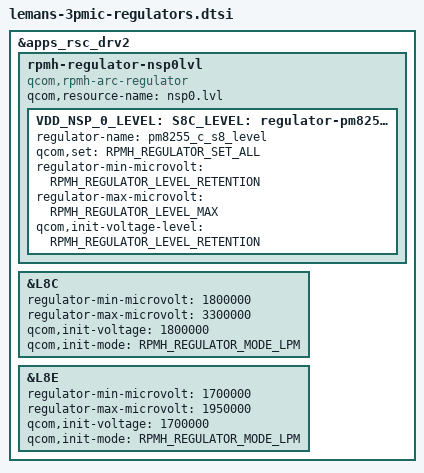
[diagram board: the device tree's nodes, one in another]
#include "lemans-4pmic-regulators.dtsi"

&apps_rsc_drv2 {
	/delete-node/ rpmh-regulator-nsp0lvl;
	/delete-node/ rpmh-regulator-nsp1lvl;

	rpmh-regulator-nsp0lvl {
		compatible = "qcom,rpmh-arc-regulator";
		qcom,resource-name = "nsp0.lvl";
		VDD_NSP_0_LEVEL:
		S8C_LEVEL:
		pm8255_c_s8_level: regulator-pm8255_c-s8-level {
			regulator-name = "pm8255_c_s8_level";
			qcom,set = <RPMH_REGULATOR_SET_ALL>;
			regulator-min-microvolt =
				<RPMH_REGULATOR_LEVEL_RETENTION>;
			regulator-max-microvolt =
				<RPMH_REGULATOR_LEVEL_MAX>;
			qcom,init-voltage-level =
				<RPMH_REGULATOR_LEVEL_RETENTION>;
		};
	};

	&L8C {
		regulator-min-microvolt = <1800000>;
		regulator-max-microvolt = <3300000>;
		qcom,init-voltage = <1800000>;
		qcom,init-mode =
			<RPMH_REGULATOR_MODE_LPM>;
	};

	&L8E {
		regulator-min-microvolt = <1700000>;
		regulator-max-microvolt = <1950000>;
		qcom,init-voltage = <1700000>;
		qcom,init-mode =
			<RPMH_REGULATOR_MODE_LPM>;
	};
};
